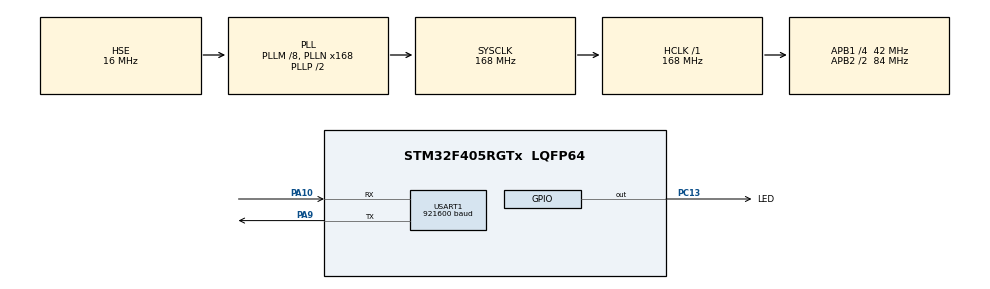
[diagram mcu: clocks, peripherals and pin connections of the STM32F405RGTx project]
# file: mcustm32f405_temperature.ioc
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ADC1.Channel-0\#ChannelRegularConversion=ADC_CHANNEL_TEMPSENSOR
ADC1.Channel-1\#ChannelRegularConversion=ADC_CHANNEL_VREFINT
ADC1.DMAContinuousRequests=ENABLE
ADC1.ExternalTrigConv=ADC_EXTERNALTRIGCONV_T3_TRGO
ADC1.InjNumberOfConversion=0
ADC1.NbrOfConversion=2
ADC1.NbrOfConversionFlag=1
ADC1.Rank-0\#ChannelRegularConversion=1
ADC1.Rank-1\#ChannelRegularConversion=2
ADC1.SamplingTime-0\#ChannelRegularConversion=ADC_SAMPLETIME_84CYCLES
ADC1.SamplingTime-1\#ChannelRegularConversion=ADC_SAMPLETIME_84CYCLES
ADC1.ScanConvMode=ENABLE
ADC1.master=1
Dma.ADC1.0.Direction=DMA_PERIPH_TO_MEMORY
Dma.ADC1.0.FIFOMode=DMA_FIFOMODE_DISABLE
Dma.ADC1.0.Instance=DMA2_Stream0
Dma.ADC1.0.MemDataAlignment=DMA_MDATAALIGN_HALFWORD
Dma.ADC1.0.MemInc=DMA_MINC_ENABLE
Dma.ADC1.0.Mode=DMA_CIRCULAR
Dma.ADC1.0.PeriphDataAlignment=DMA_PDATAALIGN_HALFWORD
Dma.ADC1.0.PeriphInc=DMA_PINC_DISABLE
Dma.ADC1.0.Priority=DMA_PRIORITY_LOW
Dma.Request0=ADC1
Mcu.Family=STM32F4
Mcu.Name=STM32F405RGTx
Mcu.Package=LQFP64
NVIC.ADC_IRQn=true\:0\:0\:false\:false\:true\:true\:true\:true
NVIC.DMA2_Stream0_IRQn=true\:0\:0\:false\:false\:true\:false\:true\:true
NVIC.PriorityGroup=NVIC_PRIORITYGROUP_4
NVIC.TIM3_IRQn=true\:0\:0\:false\:false\:true\:true\:true\:true
PA10.Mode=Asynchronous
PA10.Signal=USART1_RX
PA13.Mode=Trace_Asynchronous_SW
PA13.Signal=SYS_JTMS-SWDIO
PA14.Mode=Trace_Asynchronous_SW
PA14.Signal=SYS_JTCK-SWCLK
PA9.Mode=Asynchronous
PA9.Signal=USART1_TX
PB3.Mode=Trace_Asynchronous_SW
PB3.Signal=SYS_JTDO-SWO
PC13-ANTI_TAMP.GPIO_Label=LED
PC13-ANTI_TAMP.GPIO_ModeDefaultOutputPP=GPIO_MODE_OUTPUT_OD
PC13-ANTI_TAMP.GPIO_PuPd=GPIO_NOPULL
PC13-ANTI_TAMP.Signal=GPIO_Output
PH0-OSC_IN.Mode=HSE-External-Oscillator
PH0-OSC_IN.Signal=RCC_OSC_IN
PH1-OSC_OUT.Mode=HSE-External-Oscillator
PH1-OSC_OUT.Signal=RCC_OSC_OUT
ProjectManager.HeapSize=0x200
ProjectManager.StackSize=0x400
ProjectManager.TargetToolchain=STM32CubeIDE
RCC.48MHZClocksFreq_Value=84000000
RCC.AHBFreq_Value=168000000
RCC.APB1CLKDivider=RCC_HCLK_DIV4
RCC.APB1Freq_Value=42000000
RCC.APB1TimFreq_Value=84000000
RCC.APB2CLKDivider=RCC_HCLK_DIV2
RCC.APB2Freq_Value=84000000
RCC.APB2TimFreq_Value=168000000
RCC.CortexFreq_Value=168000000
RCC.HCLKFreq_Value=168000000
RCC.HSE_VALUE=16000000
RCC.HSI_VALUE=16000000
RCC.LSE_VALUE=32768
RCC.PLLM=8
RCC.PLLN=168
RCC.PLLSourceVirtual=RCC_PLLSOURCE_HSE
RCC.SYSCLKFreq_VALUE=168000000
RCC.SYSCLKSource=RCC_SYSCLKSOURCE_PLLCLK
RCC.VCOOutputFreq_Value=336000000
TIM3.AutoReloadPreload=TIM_AUTORELOAD_PRELOAD_ENABLE
TIM3.Period=999
TIM3.Prescaler=83
TIM3.TIM_MasterOutputTrigger=TIM_TRGO_UPDATE
USART1.BaudRate=921600
USART1.VirtualMode=VM_ASYNC
VP_ADC1_TempSens_Input.Mode=IN-TempSens
VP_ADC1_Vref_Input.Mode=IN-Vrefint
VP_TIM3_VS_ClockSourceINT.Mode=Internal
board=custom

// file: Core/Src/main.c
/* USER CODE BEGIN Header */
/**
 ******************************************************************************
 * @file           : main.c
 * @brief          : Main program body
 ******************************************************************************
 * @attention
 *
 * Copyright (c) 2024 STMicroelectronics.
 * All rights reserved.
 *
 * This software is licensed under terms that can be found in the LICENSE file
 * in the root directory of this software component.
 * If no LICENSE file comes with this software, it is provided AS-IS.
 *
 ******************************************************************************
 */
/* USER CODE END Header */
#include "main.h"

/* USER CODE BEGIN PD */
#define ADC_RESOLUTION 4095
#define ADC_SAMPLES 100
/* USER CODE END PD */

ADC_HandleTypeDef hadc1;
DMA_HandleTypeDef hdma_adc1;

TIM_HandleTypeDef htim3;

UART_HandleTypeDef huart1;

/* USER CODE BEGIN PV */
uint16_t adc_buffer[ADC_SAMPLES * 2 * 2] = { 0 }; // ADC_SAMPLES samples, 2 channels, 2 buffers

uint32_t tim_cnt = 0;

uint16_t vref_avg = 0;
uint16_t temp_avg = 0;
float vdda = 0; // Result of VDDA calculation
float vref = 0; // Result of vref calculation
float temp = 0; // Result of temp calculation
//uint32_t vdda = 0; // Result of VDDA calculation
//uint32_t vref = 0; // Result of vref calculation
//uint32_t temp = 0; // Result of temp calculation

/* USER CODE END PV */

void SystemClock_Config(void);
static void MX_GPIO_Init(void);
static void MX_DMA_Init(void);
static void MX_USART1_UART_Init(void);
static void MX_ADC1_Init(void);
static void MX_TIM3_Init(void);

/* USER CODE BEGIN 0 */

// Send stdout to USART1 and stderr to SWO
int _write(int fd, char *ptr, int len) {

    if (fd == 1) {
        HAL_StatusTypeDef hstatus;
        hstatus = HAL_UART_Transmit(&huart1, (uint8_t*) ptr, len, HAL_MAX_DELAY);
        if (hstatus == HAL_OK)
            return len;
        else
            return -1;
    } else if (fd == 2) {
        for (int i = 0; i < len; i++) {
            ITM_SendChar(ptr[i]); /* core_cm4.h */
        }
        return len;
    }
    return -1;
}

void HAL_TIM_PeriodElapsedCallback(TIM_HandleTypeDef *htim) {
    if (htim->Instance == TIM3) {
        ++tim_cnt;
    }
}

// Process half a buffer full of data
static inline void process_adc_buffer(uint16_t *buffer) {

    uint32_t sum1 = 0, sum2 = 0;
    for (int i = 0; i < ADC_SAMPLES; ++i) {
        sum1 += buffer[i * 2];
        sum2 += buffer[1 + i * 2];
    }

    vref_avg = sum2 / ADC_SAMPLES;
    temp_avg = sum1 / ADC_SAMPLES;

    // VDDA can be calculated based on the measured vref and the calibration data
    vdda = (float) VREFINT_CAL_VREF * *VREFINT_CAL_ADDR / vref_avg / 1000;
    //vdda = VREFINT_CAL_VREF * *VREFINT_CAL_ADDR / vref_avg / 1000;

    // Knowing vdda and the resolution of adc - the actual voltage can be calculated
    vref = (float)( vdda / ADC_RESOLUTION * vref_avg );
    //vref = __LL_ADC_CALC_VREFANALOG_VOLTAGE(vref_avg, ADC_RESOLUTION_12B);

    temp = (float) ( (float)( (float)(TEMPSENSOR_CAL2_TEMP - TEMPSENSOR_CAL1_TEMP) / (float)(*TEMPSENSOR_CAL2_ADDR - *TEMPSENSOR_CAL1_ADDR)) * (temp_avg - *TEMPSENSOR_CAL1_ADDR) + TEMPSENSOR_CAL1_TEMP);
    //temp = __LL_ADC_CALC_TEMPERATURE(vref, temp_avg, ADC_RESOLUTION_12B);
}

void HAL_ADC_ConvHalfCpltCallback(ADC_HandleTypeDef *hadc) {
    process_adc_buffer(&adc_buffer[0]); // We're half way through the buffer, so can safely deal with first half
}

void HAL_ADC_ConvCpltCallback(ADC_HandleTypeDef *hadc) {
    process_adc_buffer(&adc_buffer[ADC_SAMPLES * 2]); // We're all the way through the buffer, so deal with second half
}

/* USER CODE END 0 */

int main(void)
{

  /* MCU Configuration--------------------------------------------------------*/

  /* Reset of all peripherals, Initializes the Flash interface and the Systick. */
  HAL_Init();

  /* Configure the system clock */
  SystemClock_Config();

  /* Initialize all configured peripherals */
  MX_GPIO_Init();
  MX_DMA_Init();
  MX_USART1_UART_Init();
  MX_ADC1_Init();
  MX_TIM3_Init();
  /* USER CODE BEGIN 2 */

    DBG("\n\n\n\nStarting\n--------");

    printf("VREFINT_CAL = %d (0x%04x)\n", (uint16_t) *VREFINT_CAL_ADDR, (uint16_t) *VREFINT_CAL_ADDR);
    printf("TEMP1 = %d TEMPSENSOR_CAL1 = %d (0x%04x)\n", (uint16_t)TEMPSENSOR_CAL1_TEMP, *TEMPSENSOR_CAL1_ADDR, (uint16_t)*TEMPSENSOR_CAL1_ADDR);
    printf("TEMP2 = %d TEMPSENSOR_CAL2 = %d (0x%04x)\n", (uint16_t)TEMPSENSOR_CAL2_TEMP, *TEMPSENSOR_CAL2_ADDR, (uint16_t)*TEMPSENSOR_CAL2_ADDR);

    HAL_TIM_Base_Start_IT(&htim3); // First get the timer running

    HAL_ADC_Start_DMA(&hadc1, (uint32_t*) adc_buffer, ADC_SAMPLES * 2 * 2); // Now fire up the ADC DMA

  /* USER CODE END 2 */

  /* Infinite loop */
  /* USER CODE BEGIN WHILE */

    uint32_t now = 0, last_blink = 0, last_tick = 0;

    while (1)
    {

        now = HAL_GetTick();

        if (now - last_blink >= 500) {
            HAL_GPIO_TogglePin(LED_GPIO_Port, LED_Pin);
            last_blink = now;
        }

        if (now - last_tick >= 1000) {
            DBG("VDDA = %5.3f V Vref = %5.3f V (raw = %d) Temp = %4.2f °C (raw = %d)", (float)vdda, (float)vref, vref_avg, (float)temp, temp_avg);
            last_tick = now;
        }

    /* USER CODE END WHILE */

    }
}

void SystemClock_Config(void)
{
  RCC_OscInitTypeDef RCC_OscInitStruct = {0};
  RCC_ClkInitTypeDef RCC_ClkInitStruct = {0};

  /** Configure the main internal regulator output voltage
  */
  __HAL_RCC_PWR_CLK_ENABLE();
  __HAL_PWR_VOLTAGESCALING_CONFIG(PWR_REGULATOR_VOLTAGE_SCALE1);

  /** Initializes the RCC Oscillators according to the specified parameters
  * in the RCC_OscInitTypeDef structure.
  */
  RCC_OscInitStruct.OscillatorType = RCC_OSCILLATORTYPE_HSE;
  RCC_OscInitStruct.HSEState = RCC_HSE_ON;
  RCC_OscInitStruct.PLL.PLLState = RCC_PLL_ON;
  RCC_OscInitStruct.PLL.PLLSource = RCC_PLLSOURCE_HSE;
  RCC_OscInitStruct.PLL.PLLM = 8;
  RCC_OscInitStruct.PLL.PLLN = 168;
  RCC_OscInitStruct.PLL.PLLP = RCC_PLLP_DIV2;
  RCC_OscInitStruct.PLL.PLLQ = 4;
  if (HAL_RCC_OscConfig(&RCC_OscInitStruct) != HAL_OK)
  {
    Error_Handler();
  }

  /** Initializes the CPU, AHB and APB buses clocks
  */
  RCC_ClkInitStruct.ClockType = RCC_CLOCKTYPE_HCLK|RCC_CLOCKTYPE_SYSCLK
                              |RCC_CLOCKTYPE_PCLK1|RCC_CLOCKTYPE_PCLK2;
  RCC_ClkInitStruct.SYSCLKSource = RCC_SYSCLKSOURCE_PLLCLK;
  RCC_ClkInitStruct.AHBCLKDivider = RCC_SYSCLK_DIV1;
  RCC_ClkInitStruct.APB1CLKDivider = RCC_HCLK_DIV4;
  RCC_ClkInitStruct.APB2CLKDivider = RCC_HCLK_DIV2;

  if (HAL_RCC_ClockConfig(&RCC_ClkInitStruct, FLASH_LATENCY_5) != HAL_OK)
  {
    Error_Handler();
  }
}

static void MX_ADC1_Init(void)
{

  ADC_ChannelConfTypeDef sConfig = {0};

  /** Configure the global features of the ADC (Clock, Resolution, Data Alignment and number of conversion)
  */
  hadc1.Instance = ADC1;
  hadc1.Init.ClockPrescaler = ADC_CLOCK_SYNC_PCLK_DIV4;
  hadc1.Init.Resolution = ADC_RESOLUTION_12B;
  hadc1.Init.ScanConvMode = ENABLE;
  hadc1.Init.ContinuousConvMode = DISABLE;
  hadc1.Init.DiscontinuousConvMode = DISABLE;
  hadc1.Init.ExternalTrigConvEdge = ADC_EXTERNALTRIGCONVEDGE_RISING;
  hadc1.Init.ExternalTrigConv = ADC_EXTERNALTRIGCONV_T3_TRGO;
  hadc1.Init.DataAlign = ADC_DATAALIGN_RIGHT;
  hadc1.Init.NbrOfConversion = 2;
  hadc1.Init.DMAContinuousRequests = ENABLE;
  hadc1.Init.EOCSelection = ADC_EOC_SINGLE_CONV;
  if (HAL_ADC_Init(&hadc1) != HAL_OK)
  {
    Error_Handler();
  }

  /** Configure for the selected ADC regular channel its corresponding rank in the sequencer and its sample time.
  */
  sConfig.Channel = ADC_CHANNEL_TEMPSENSOR;
  sConfig.Rank = 1;
  sConfig.SamplingTime = ADC_SAMPLETIME_84CYCLES;
  if (HAL_ADC_ConfigChannel(&hadc1, &sConfig) != HAL_OK)
  {
    Error_Handler();
  }

  /** Configure for the selected ADC regular channel its corresponding rank in the sequencer and its sample time.
  */
  sConfig.Channel = ADC_CHANNEL_VREFINT;
  sConfig.Rank = 2;
  if (HAL_ADC_ConfigChannel(&hadc1, &sConfig) != HAL_OK)
  {
    Error_Handler();
  }

}

static void MX_TIM3_Init(void)
{

  TIM_ClockConfigTypeDef sClockSourceConfig = {0};
  TIM_MasterConfigTypeDef sMasterConfig = {0};

  htim3.Instance = TIM3;
  htim3.Init.Prescaler = 83;
  htim3.Init.CounterMode = TIM_COUNTERMODE_UP;
  htim3.Init.Period = 999;
  htim3.Init.ClockDivision = TIM_CLOCKDIVISION_DIV1;
  htim3.Init.AutoReloadPreload = TIM_AUTORELOAD_PRELOAD_ENABLE;
  if (HAL_TIM_Base_Init(&htim3) != HAL_OK)
  {
    Error_Handler();
  }
  sClockSourceConfig.ClockSource = TIM_CLOCKSOURCE_INTERNAL;
  if (HAL_TIM_ConfigClockSource(&htim3, &sClockSourceConfig) != HAL_OK)
  {
    Error_Handler();
  }
  sMasterConfig.MasterOutputTrigger = TIM_TRGO_UPDATE;
  sMasterConfig.MasterSlaveMode = TIM_MASTERSLAVEMODE_DISABLE;
  if (HAL_TIMEx_MasterConfigSynchronization(&htim3, &sMasterConfig) != HAL_OK)
  {
    Error_Handler();
  }

}

static void MX_USART1_UART_Init(void)
{

  huart1.Instance = USART1;
  huart1.Init.BaudRate = 921600;
  huart1.Init.WordLength = UART_WORDLENGTH_8B;
  huart1.Init.StopBits = UART_STOPBITS_1;
  huart1.Init.Parity = UART_PARITY_NONE;
  huart1.Init.Mode = UART_MODE_TX_RX;
  huart1.Init.HwFlowCtl = UART_HWCONTROL_NONE;
  huart1.Init.OverSampling = UART_OVERSAMPLING_16;
  if (HAL_UART_Init(&huart1) != HAL_OK)
  {
    Error_Handler();
  }

}

static void MX_DMA_Init(void)
{

  /* DMA controller clock enable */
  __HAL_RCC_DMA2_CLK_ENABLE();

  /* DMA interrupt init */
  /* DMA2_Stream0_IRQn interrupt configuration */
  HAL_NVIC_SetPriority(DMA2_Stream0_IRQn, 0, 0);
  HAL_NVIC_EnableIRQ(DMA2_Stream0_IRQn);

}

static void MX_GPIO_Init(void)
{
  GPIO_InitTypeDef GPIO_InitStruct = {0};

  /* GPIO Ports Clock Enable */
  __HAL_RCC_GPIOC_CLK_ENABLE();
  __HAL_RCC_GPIOH_CLK_ENABLE();
  __HAL_RCC_GPIOA_CLK_ENABLE();
  __HAL_RCC_GPIOB_CLK_ENABLE();

  /*Configure GPIO pin Output Level */
  HAL_GPIO_WritePin(LED_GPIO_Port, LED_Pin, GPIO_PIN_RESET);

  /*Configure GPIO pin : LED_Pin */
  GPIO_InitStruct.Pin = LED_Pin;
  GPIO_InitStruct.Mode = GPIO_MODE_OUTPUT_OD;
  GPIO_InitStruct.Pull = GPIO_NOPULL;
  GPIO_InitStruct.Speed = GPIO_SPEED_FREQ_LOW;
  HAL_GPIO_Init(LED_GPIO_Port, &GPIO_InitStruct);

}

void Error_Handler(void)
{
    __disable_irq();
    while (1)
    {
    }
}
